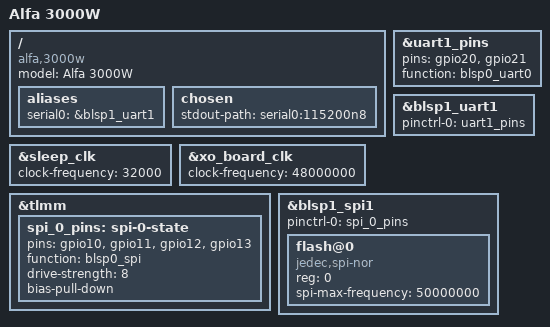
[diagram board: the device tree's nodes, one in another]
// SPDX-License-Identifier: GPL-2.0+ OR BSD-3-Clause
/*
 * Alfa 3000W DTS
 *
 */

/dts-v1/;

#include "ipq5018.dtsi"

/ {
	model = "Alfa 3000W";
	compatible = "alfa,3000w", "qcom,ipq5018";

	aliases {
		serial0 = &blsp1_uart1;
	};

	chosen {
		stdout-path = "serial0:115200n8";
	};
};

&uart1_pins {
	pins = "gpio20", "gpio21";
	function = "blsp0_uart0";
};

&blsp1_uart1 {
	status = "okay";

	pinctrl-0 = <&uart1_pins>;
	pinctrl-names = "default";
};

&sleep_clk {
	clock-frequency = <32000>;
};

&xo_board_clk {
	clock-frequency = <48000000>;
};

&tlmm {
	spi_0_pins: spi-0-state {
		pins = "gpio10", "gpio11", "gpio12", "gpio13";
		function = "blsp0_spi";
		drive-strength = <8>;
		bias-pull-down;
	};
};

&blsp1_spi1 {
	status = "okay";

	pinctrl-0 = <&spi_0_pins>;
	pinctrl-names = "default";

	flash@0 {
		#address-cells = <1>;
		#size-cells = <1>;
		reg = <0>;
		compatible = "jedec,spi-nor";
		spi-max-frequency = <50000000>;
	};
};
